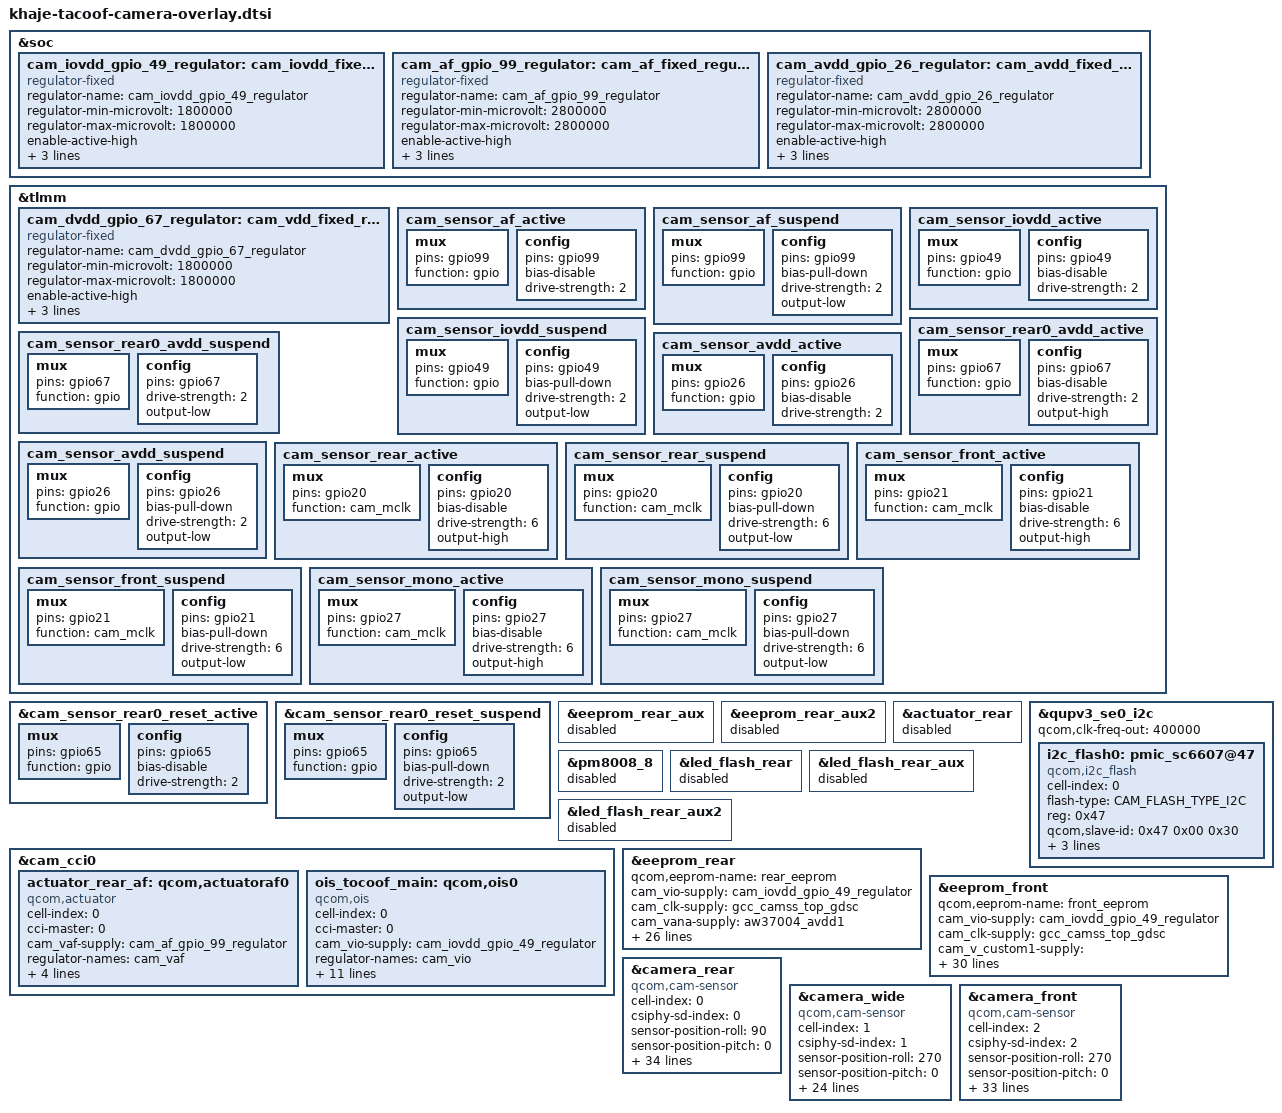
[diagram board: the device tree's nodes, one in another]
//khaje-camera-sensor-qrd.dtsi

&soc {
    cam_iovdd_gpio_49_regulator:cam_iovdd_fixed_regulator {
        compatible = "regulator-fixed";
        regulator-name = "cam_iovdd_gpio_49_regulator";
        regulator-min-microvolt = <1800000>;
        regulator-max-microvolt = <1800000>;
        enable-active-high;
        gpio = <&tlmm 49 0>;
        pinctrl-names = "cam_default","cam_suspend";
        pinctrl-0 = <&cam_sensor_iovdd_active>;
        pinctrl-1 = <&cam_sensor_iovdd_suspend>;
    };

    cam_af_gpio_99_regulator:cam_af_fixed_regulator {
        compatible = "regulator-fixed";
        regulator-name = "cam_af_gpio_99_regulator";
        regulator-min-microvolt = <2800000>;
        regulator-max-microvolt = <2800000>;
        enable-active-high;
        gpio = <&tlmm 99 0>;
        pinctrl-names = "cam_default","cam_suspend";
        pinctrl-0 = <&cam_sensor_af_active>;
        pinctrl-1 = <&cam_sensor_af_suspend>;
    };

    cam_avdd_gpio_26_regulator:cam_avdd_fixed_regulator {
        compatible = "regulator-fixed";
        regulator-name = "cam_avdd_gpio_26_regulator";
        regulator-min-microvolt = <2800000>;
        regulator-max-microvolt = <2800000>;
        enable-active-high;
        gpio = <&tlmm 26 0>;
        pinctrl-names = "cam_default","cam_suspend";
        pinctrl-0 = <&cam_sensor_avdd_active>;
        pinctrl-1 = <&cam_sensor_avdd_suspend>;
    };
};

&tlmm {
    cam_dvdd_gpio_67_regulator:cam_vdd_fixed_regulator {
        compatible = "regulator-fixed";
        regulator-name = "cam_dvdd_gpio_67_regulator";
        regulator-min-microvolt = <1800000>;
        regulator-max-microvolt = <1800000>;
        enable-active-high;
        gpio = <&tlmm 67 0>;
        pinctrl-names = "cam_default","cam_suspend";
        pinctrl-0 = <&cam_sensor_rear0_avdd_active>;
        pinctrl-1 = <&cam_sensor_rear0_avdd_suspend>;
    };
     cam_sensor_af_active: cam_sensor_af_active {
        mux {
            pins = "gpio99";
            function = "gpio";
        };

        config {
            pins = "gpio99";
            bias-disable; /* No PULL */
            drive-strength = <2>; /* 2 MA */
        };
    };
    cam_sensor_af_suspend: cam_sensor_af_suspend {
        mux {
            pins = "gpio99";
            function = "gpio";
        };

        config {
            pins = "gpio99";
            bias-pull-down; /* PULL DOWN */
            drive-strength = <2>; /* 2 MA */
            output-low;
        };
    };
    cam_sensor_iovdd_active: cam_sensor_iovdd_active {
        mux {
            pins = "gpio49";
            function = "gpio";
        };
        config {
            pins = "gpio49";
            bias-disable; /* No PULL */
            drive-strength = <2>; /* 2 MA */
        };
    };
    cam_sensor_iovdd_suspend: cam_sensor_iovdd_suspend {
        mux {
            pins = "gpio49";
            function = "gpio";
        };
        config {
            pins = "gpio49";
            bias-pull-down; /* PULL DOWN */
            drive-strength = <2>; /* 2 MA */
            output-low;
        };
    };

    cam_sensor_rear0_avdd_active: cam_sensor_rear0_avdd_active {
        mux {
            pins = "gpio67";
            function = "gpio";
        };
        config {
            pins = "gpio67";
            bias-disable; /* No PULL */
            drive-strength = <2>; /* 2 MA */
            output-high;
        };
    };
    cam_sensor_rear0_avdd_suspend: cam_sensor_rear0_avdd_suspend {
        mux {
            pins = "gpio67";
            function = "gpio";
        };
        config {
            pins = "gpio67";
            drive-strength = <2>; /* 2 MA */
            output-low;
        };
    };
    cam_sensor_avdd_active: cam_sensor_avdd_active {
        mux {
            pins = "gpio26";
            function = "gpio";
        };
        config {
            pins = "gpio26";
            bias-disable; /* No PULL */
            drive-strength = <2>; /* 2 MA */
        };
    };

    cam_sensor_avdd_suspend: cam_sensor_avdd_suspend {
        mux {
            pins = "gpio26";
            function = "gpio";
        };
        config {
            pins = "gpio26";
            bias-pull-down; /* PULL DOWN */
            drive-strength = <2>; /* 2 MA */
            output-low;
        };
    };

    cam_sensor_rear_active: cam_sensor_rear_active {
        mux {
            pins = "gpio20";
            function = "cam_mclk";
        };
        config {
            pins = "gpio20";
            bias-disable; /* No PULL */
            drive-strength = <6>; /* 6 MA */
            output-high;
        };
    };
    cam_sensor_rear_suspend: cam_sensor_rear_suspend {
        mux {
            pins = "gpio20";
            function = "cam_mclk";
        };
        config {
            pins = "gpio20";
            bias-pull-down; /* PULL DOWN */
            drive-strength = <6>; /* 6 MA */
            output-low;
        };
    };

    cam_sensor_front_active: cam_sensor_front_active {
        mux {
            pins = "gpio21";
            function = "cam_mclk";
        };
        config {
            pins = "gpio21";
            bias-disable; /* No PULL */
            drive-strength = <6>; /* 6 MA */
            output-high;
        };
    };
    cam_sensor_front_suspend: cam_sensor_front_suspend {
        mux {
            pins = "gpio21";
            function = "cam_mclk";
        };
        config {
            pins = "gpio21";
            bias-pull-down; /* PULL DOWN */
            drive-strength = <6>; /* 6 MA */
            output-low;
        };
    };

    cam_sensor_mono_active: cam_sensor_mono_active {
        mux {
            pins = "gpio27";
            function = "cam_mclk";
        };
        config {
            pins = "gpio27";
            bias-disable; /* No PULL */
            drive-strength = <6>; /* 6 MA */
            output-high;
        };
    };
    cam_sensor_mono_suspend: cam_sensor_mono_suspend {
        mux {
            pins = "gpio27";
            function = "cam_mclk";
        };
        config {
            pins = "gpio27";
            bias-pull-down; /* PULL DOWN */
            drive-strength = <6>; /* 6 MA */
            output-low;
        };
    };
};
&cam_sensor_rear0_reset_active {
    mux {
        pins = "gpio65";
        function = "gpio";
    };
    config {
        pins = "gpio65";
        bias-disable; /* No PULL */
        drive-strength = <2>; /* 2 MA */
    };
};

&cam_sensor_rear0_reset_suspend {
    mux {
        pins = "gpio65";
        function = "gpio";
    };
    config {
        pins = "gpio65";
        bias-pull-down; /* PULL DOWN */
        drive-strength = <2>; /* 2 MA */
        output-low;
    };
};

&eeprom_rear_aux {
    status = "disabled";
};

&eeprom_rear_aux2 {
    status = "disabled";
};

&actuator_rear {
    status = "disable";
};

&qupv3_se0_i2c {
    status = "ok";
    qcom,clk-freq-out = <400000>;
    i2c_flash0:pmic_sc6607@47 {
             status = "ok";
             cell-index = <0>;
             compatible = "qcom,i2c_flash";
             flash-type = <CAM_FLASH_TYPE_I2C>;
             reg = <0x47>;
             qcom,slave-id = <0x47 0x00 0x30>;
             qcom,flash-name = "i2c_flash";
             qcom,flash-type = <1>;
             flash-index = <5>;
    };
};

&pm8008_8 {
    status = "disabled";
};
&led_flash_rear {
	status = "disabled";
};

&led_flash_rear_aux{
    status = "disabled";
};
&led_flash_rear_aux2{
    status = "disabled";
};

&cam_cci0 {
        actuator_rear_af: qcom,actuatoraf0 {
                cell-index = <0>;
                compatible = "qcom,actuator";
                cci-master = <0>;
                cam_vaf-supply = <&cam_af_gpio_99_regulator>;
                regulator-names = "cam_vaf";
                rgltr-cntrl-support;
                rgltr-min-voltage = <2800000>;
                rgltr-max-voltage = <2800000>;
                rgltr-load-current = <100000>;
                status = "ok";
        };
        ois_tocoof_main: qcom,ois0 {
                cell-index = <0>;
                compatible = "qcom,ois";
                cci-master = <0>;
                cam_vio-supply = <&cam_iovdd_gpio_49_regulator>;
                regulator-names = "cam_vio";
                rgltr-cntrl-support;
                rgltr-min-voltage = <1800000>;
                rgltr-max-voltage = <1800000>;
                rgltr-load-current = <300000>;
                ois_gyro,position=<3>;
                ois_gyro,type=<3>;
                ois,type=<0>;
                ois,name="dw9828n";
                ois_module,vendor=<1>;
                ois_actuator,vendor=<2>;
                ois,fw=<0>;
                status = "ok";
        };
};

&eeprom_rear {
                qcom,eeprom-name = "rear_eeprom";
                cam_vio-supply = <&cam_iovdd_gpio_49_regulator>;
                cam_clk-supply = <&gcc_camss_top_gdsc>;
                cam_vana-supply = <&aw37004_avdd1>;
                cam_vdig-supply = <&aw37004_dvdd1>;
                regulator-names = "cam_vio","cam_clk","cam_vana","cam_vdig";
                rgltr-cntrl-support;
                pwm-switch;
                rgltr-min-voltage = <1800000 0 2800000 1104000 >;
                rgltr-max-voltage = <1800000 0 2800000 1104000 >;
                rgltr-load-current = <120000 0 120000 120000 >;
                gpio-no-mux = <0>;
                pinctrl-names = "cam_default", "cam_suspend";
                pinctrl-0 = <&cam_sensor_rear_active
                            &cam_sensor_rear0_reset_active
                            &cam_sensor_rear0_avdd_active>;
                pinctrl-1 = <&cam_sensor_rear_suspend
                            &cam_sensor_rear0_reset_suspend
                            &cam_sensor_rear0_avdd_suspend>;
                gpios = <&tlmm 20 0>,
                        <&tlmm 65 0>,
                        <&tlmm 67 0>;
                gpio-reset = <1>;
                gpio-custom1 = <2>;
                gpio-req-tbl-num = <0 1 2>;
                gpio-req-tbl-flags = <1 0 0>;
                gpio-req-tbl-label = "CAMIF_MCLK0",
                                     "CAM_RESET0",
                                     "CAM_CUSTOM0";
                cci-master = <0>;
                status = "ok";
                clocks = <&gcc GCC_CAMSS_MCLK0_CLK>;
                clock-names = "cam_clk";
                clock-cntl-level = "turbo";
                clock-rates = <24000000>;
};

&eeprom_front {
        qcom,eeprom-name = "front_eeprom";
        cam_vio-supply = <&cam_iovdd_gpio_49_regulator>;
        cam_clk-supply = <&gcc_camss_top_gdsc>;
        cam_v_custom1-supply = <&cam_dvdd_gpio_67_regulator>;
        cam_vana-supply = <&aw37004_avdd2>;
        cam_vdig-supply = <&aw37004_dvdd2>;
        regulator-names = "cam_vio","cam_clk","cam_v_custom1","cam_vana","cam_vdig";
        rgltr-cntrl-support;
        pwm-switch;
        rgltr-min-voltage = <1800000 0 1800000 2800000 1200000>;
        rgltr-max-voltage = <1800000 0 1800000 2800000 1200000>;
        rgltr-load-current = <120000 0 120000 120000 120000>;
        gpio-no-mux = <0>;
        pinctrl-names = "cam_default", "cam_suspend";
        pinctrl-0 = <&cam_sensor_front_active
                     &cam_sensor_rear1_reset_active
                     &cam_sensor_rear0_avdd_active>;
        pinctrl-1 = <&cam_sensor_front_suspend
                     &cam_sensor_rear1_reset_suspend
                     &cam_sensor_rear0_avdd_suspend>;
        gpios = <&tlmm 21 0>,
                <&tlmm 19 0>,
                <&tlmm 67 0>;
        gpio-reset = <1>;
        gpio-req-tbl-num = <0 1>;
        gpio-req-tbl-flags = <1 0>;
        gpio-req-tbl-label = "CAMIF_MCLK1",
                             "CAM_RESET2",
                             "CAM_CUSTOM0";
        cci-master = <1>;
        status = "ok";
        clocks = <&gcc GCC_CAMSS_MCLK1_CLK>;
        clock-names = "cam_clk";
        clock-cntl-level = "turbo";
        clock-rates = <24000000>;
};

&camera_rear {
                cell-index = <0>;
                compatible = "qcom,cam-sensor";
                csiphy-sd-index = <0>;
                sensor-position-roll = <90>;
                sensor-position-pitch = <0>;
                sensor-position-yaw = <180>;
                actuator-src = <&actuator_rear_af>;
                ois-src = <&ois_tocoof_main>;
                eeprom-src = <&eeprom_rear>;
                led-flash-src = <&i2c_flash0>;
                cam_vio-supply = <&cam_iovdd_gpio_49_regulator>;
                cam_clk-supply = <&gcc_camss_top_gdsc>;
                cam_vana-supply = <&aw37004_avdd1>;
                cam_vdig-supply = <&aw37004_dvdd1>;
                regulator-names = "cam_vio","cam_clk","cam_vana","cam_vdig";
                rgltr-cntrl-support;
                pwm-switch;
                rgltr-min-voltage = <1800000 0 2800000 1104000 >;
                rgltr-max-voltage = <1800000 0 2800000 1104000 >;
                rgltr-load-current = <120000 0 120000 120000 >;
                gpio-no-mux = <0>;
                pinctrl-names = "cam_default", "cam_suspend";
                pinctrl-0 = <&cam_sensor_rear_active
                            &cam_sensor_rear0_reset_active
                            &cam_sensor_rear0_avdd_active>;
                pinctrl-1 = <&cam_sensor_rear_suspend
                            &cam_sensor_rear0_reset_suspend
                            &cam_sensor_rear0_avdd_suspend>;
                gpios = <&tlmm 20 0>,
                        <&tlmm 65 0>,
                        <&tlmm 67 0>;
                gpio-reset = <1>;
                gpio-custom1 = <2>;
                gpio-req-tbl-num = <0 1 2>;
                gpio-req-tbl-flags = <1 0 0>;
                gpio-req-tbl-label = "CAMIF_MCLK0",
                                     "CAM_RESET0",
                                     "CAM_CUSTOM0";
                cci-master = <0>;
                status = "ok";
                clocks = <&gcc GCC_CAMSS_MCLK0_CLK>;
                clock-names = "cam_clk";
                clock-cntl-level = "turbo";
                clock-rates = <24000000>;
};

// mono
&camera_wide {
        cell-index = <1>;
        compatible = "qcom,cam-sensor";
        csiphy-sd-index = <1>;
        sensor-position-roll = <270>;
        sensor-position-pitch = <0>;
        sensor-position-yaw = <180>;
        cam_vio-supply = <&cam_iovdd_gpio_49_regulator>;
        cam_clk-supply = <&gcc_camss_top_gdsc>;
        cam_vana-supply = <&cam_avdd_gpio_26_regulator>;
        regulator-names = "cam_vio","cam_clk","cam_vana";
        rgltr-cntrl-support;
        pwm-switch;
        rgltr-min-voltage = <1800000 0 2800000 >;
        rgltr-max-voltage = <1800000 0 2800000 >;
        rgltr-load-current = <120000 0 120000 >;
        gpio-no-mux = <0>;
        pinctrl-names = "cam_default", "cam_suspend";
        pinctrl-0 = <&cam_sensor_mono_active
                     &cam_sensor_rear0_reset_active>;
        pinctrl-1 = <&cam_sensor_mono_suspend
                     &cam_sensor_rear0_reset_suspend>;
        gpios = <&tlmm 27 0>,
                <&tlmm 18 0>;
        gpio-reset = <1>;
        gpio-req-tbl-num = <0 1>;
        gpio-req-tbl-flags = <1 0>;
        gpio-req-tbl-label = "CAMIF_MCLK2",
                              "CAM_RESET1";
        cci-master = <1>;
        status = "ok";
        clocks = <&gcc GCC_CAMSS_MCLK2_CLK>;
        clock-names = "cam_clk";
        clock-cntl-level = "turbo";
        clock-rates = <24000000>;
};

//FRONT
&camera_front {
        cell-index = <2>;
        compatible = "qcom,cam-sensor";
        csiphy-sd-index = <2>;
        sensor-position-roll = <270>;
        sensor-position-pitch = <0>;
        sensor-position-yaw = <0>;
        eeprom-src = <&eeprom_front>;
        cam_vio-supply = <&cam_iovdd_gpio_49_regulator>;
        cam_clk-supply = <&gcc_camss_top_gdsc>;
        cam_vana-supply = <&aw37004_avdd2>;
        cam_vdig-supply = <&aw37004_dvdd2>;
        regulator-names = "cam_vio","cam_clk","cam_v_custom1","cam_vana","cam_vdig";
        rgltr-cntrl-support;
        pwm-switch;
        rgltr-min-voltage = <1800000 0 1800000 2800000 1200000>;
        rgltr-max-voltage = <1800000 0 1800000 2800000 1200000>;
        rgltr-load-current = <120000 0 120000 120000 120000>;
        gpio-no-mux = <0>;
        pinctrl-names = "cam_default", "cam_suspend";
        pinctrl-0 = <&cam_sensor_front_active
                     &cam_sensor_rear1_reset_active
                     &cam_sensor_rear0_avdd_active>;
        pinctrl-1 = <&cam_sensor_front_suspend
                     &cam_sensor_rear1_reset_suspend
                     &cam_sensor_rear0_avdd_suspend>;
        gpios = <&tlmm 21 0>,
                <&tlmm 19 0>,
                <&tlmm 67 0>;
        gpio-reset = <1>;
        gpio-req-tbl-num = <0 1>;
        gpio-req-tbl-flags = <1 0>;
        gpio-req-tbl-label = "CAMIF_MCLK1",
                             "CAM_RESET2",
                             "CAM_CUSTOM0";
        cci-master = <1>;
        status = "ok";
        clocks = <&gcc GCC_CAMSS_MCLK1_CLK>;
        clock-names = "cam_clk";
        clock-cntl-level = "turbo";
        clock-rates = <24000000>;
};
